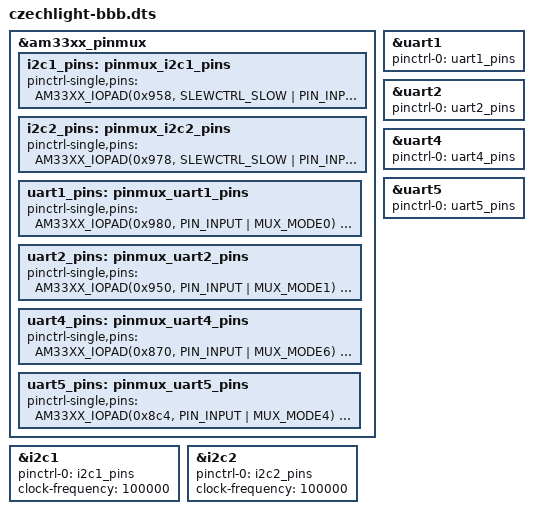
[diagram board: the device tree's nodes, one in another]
#include "am335x-boneblack.dts"

&am33xx_pinmux {
        i2c1_pins: pinmux_i2c1_pins {
                pinctrl-single,pins = <
                        AM33XX_IOPAD(0x958, SLEWCTRL_SLOW | PIN_INPUT_PULLUP | MUX_MODE2) /* P9_18, I2C1_SDA */
                        AM33XX_IOPAD(0x95c, SLEWCTRL_SLOW | PIN_INPUT_PULLUP | MUX_MODE2) /* P9_17, I2C1_SCL */
                >;
        };

        i2c2_pins: pinmux_i2c2_pins {
                pinctrl-single,pins = <
                        AM33XX_IOPAD(0x978, SLEWCTRL_SLOW | PIN_INPUT_PULLUP | MUX_MODE3) /* P9_20, I2C2_SDA */
                        AM33XX_IOPAD(0x97c, SLEWCTRL_SLOW | PIN_INPUT_PULLUP | MUX_MODE3) /* P9_19, I2C2_SCL */
                >;
        };

	uart1_pins: pinmux_uart1_pins {
		pinctrl-single,pins = <
			AM33XX_IOPAD(0x980, PIN_INPUT | MUX_MODE0) /* P9_26, uart1_rxd */
			AM33XX_IOPAD(0x984, PIN_OUTPUT | MUX_MODE0) /* P9_24, uart1_txd */
		>;
	};

	uart2_pins: pinmux_uart2_pins {
		pinctrl-single,pins = <
			AM33XX_IOPAD(0x950, PIN_INPUT | MUX_MODE1) /* P9_22, uart2_rxd */
			AM33XX_IOPAD(0x954, PIN_OUTPUT | MUX_MODE1) /* P9_21, uart2_txd */
		>;
	};

	/* UART3: mode 1, rx N/A, tx p9_42 -> not used */

	uart4_pins: pinmux_uart4_pins {
		pinctrl-single,pins = <
			AM33XX_IOPAD(0x870, PIN_INPUT | MUX_MODE6) /* P9_11, uart4_rxd */
			AM33XX_IOPAD(0x874, PIN_OUTPUT | MUX_MODE6) /* P9_13, uart4_txd */
		>;
	};

	uart5_pins: pinmux_uart5_pins {
		pinctrl-single,pins = <
			AM33XX_IOPAD(0x8c4, PIN_INPUT | MUX_MODE4) /* P8_38, uart5_rxd */
			AM33XX_IOPAD(0x8c0, PIN_OUTPUT | MUX_MODE4) /* P8_37, uart5_txd */
		>;
	};
};

&i2c1 {
        pinctrl-names = "default";
        pinctrl-0 = <&i2c1_pins>;
        clock-frequency = <100000>;
        status = "okay";
};

&i2c2 {
        pinctrl-names = "default";
        pinctrl-0 = <&i2c2_pins>;
        clock-frequency = <100000>;
        status = "okay";
};

&uart1 {
	pinctrl-names = "default";
	pinctrl-0 = <&uart1_pins>;
	status = "okay";
};

&uart2 {
	pinctrl-names = "default";
	pinctrl-0 = <&uart2_pins>;
	status = "okay";
};

&uart4 {
	pinctrl-names = "default";
	pinctrl-0 = <&uart4_pins>;
	status = "okay";
};

&uart5 {
	pinctrl-names = "default";
	pinctrl-0 = <&uart5_pins>;
	status = "okay";
};

/delete-node/ &cape_eeprom0;
/delete-node/ &cape_eeprom1;
/delete-node/ &cape_eeprom2;
/delete-node/ &cape_eeprom3;
